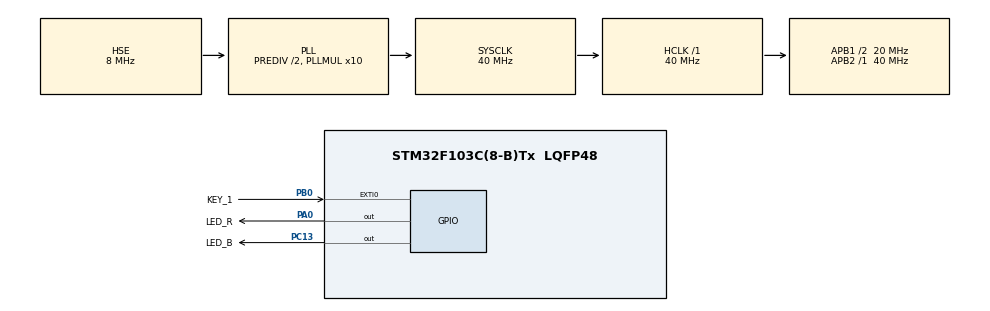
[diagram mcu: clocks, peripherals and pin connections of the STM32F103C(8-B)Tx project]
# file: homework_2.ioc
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Mcu.Family=STM32F1
Mcu.Name=STM32F103C(8-B)Tx
Mcu.Package=LQFP48
NVIC.EXTI0_IRQn=true\:3\:0\:true\:false\:true\:true\:true\:true
NVIC.PriorityGroup=NVIC_PRIORITYGROUP_4
NVIC.TIM3_IRQn=true\:0\:0\:false\:false\:true\:true\:true\:true
PA0-WKUP.GPIO_Label=LED_R
PA0-WKUP.PinState=GPIO_PIN_SET
PA0-WKUP.Signal=GPIO_Output
PA13.Mode=Serial_Wire
PA13.Signal=SYS_JTMS-SWDIO
PA14.Mode=Serial_Wire
PA14.Signal=SYS_JTCK-SWCLK
PB0.GPIO_Label=KEY_1
PB0.GPIO_ModeDefaultEXTI=GPIO_MODE_IT_RISING_FALLING
PB0.GPIO_PuPd=GPIO_PULLUP
PB0.Signal=GPXTI0
PC13-TAMPER-RTC.GPIO_Label=LED_B
PC13-TAMPER-RTC.Signal=GPIO_Output
PC14-OSC32_IN.Mode=LSE-External-Oscillator
PC14-OSC32_IN.Signal=RCC_OSC32_IN
PC15-OSC32_OUT.Mode=LSE-External-Oscillator
PC15-OSC32_OUT.Signal=RCC_OSC32_OUT
PD0-OSC_IN.Mode=HSE-External-Oscillator
PD0-OSC_IN.Signal=RCC_OSC_IN
PD1-OSC_OUT.Mode=HSE-External-Oscillator
PD1-OSC_OUT.Signal=RCC_OSC_OUT
ProjectManager.HeapSize=0x200
ProjectManager.StackSize=0x400
ProjectManager.TargetToolchain=MDK-ARM V5.32
RCC.AHBFreq_Value=40000000
RCC.APB1CLKDivider=RCC_HCLK_DIV2
RCC.APB1Freq_Value=20000000
RCC.APB1TimFreq_Value=40000000
RCC.APB2Freq_Value=40000000
RCC.APB2TimFreq_Value=40000000
RCC.HCLKFreq_Value=40000000
RCC.HSEDivPLL=RCC_HSE_PREDIV_DIV2
RCC.PLLMUL=RCC_PLL_MUL10
RCC.PLLSourceVirtual=RCC_PLLSOURCE_HSE
RCC.SYSCLKFreq_VALUE=40000000
RCC.SYSCLKSource=RCC_SYSCLKSOURCE_PLLCLK
RCC.USBFreq_Value=40000000
TIM3.AutoReloadPreload=TIM_AUTORELOAD_PRELOAD_ENABLE
TIM3.Period=3999
TIM3.Prescaler=1999
VP_TIM3_VS_ClockSourceINT.Mode=Internal
board=custom

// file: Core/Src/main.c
/* USER CODE BEGIN Header */
/**
  ******************************************************************************
  * @file           : main.c
  * @brief          : Main program body
  ******************************************************************************
  * @attention
  *
  * Copyright (c) 2026 STMicroelectronics.
  * All rights reserved.
  *
  * This software is licensed under terms that can be found in the LICENSE file
  * in the root directory of this software component.
  * If no LICENSE file comes with this software, it is provided AS-IS.
  *
  ******************************************************************************
  */
/* USER CODE END Header */
#include "main.h"
#include "tim.h"
#include "gpio.h"

/* USER CODE BEGIN PV */

//控制红色led灯开关与闪烁的变量
uint8_t key_state = 0;//记录按键的状态，未按下为0，按下为1
uint32_t last_time = 0;//上一次中断时间
uint32_t press_time = 0;//记录按下时间
uint32_t lift_time = 0;//记录抬起时间
uint8_t led_state = 0;//记录LED的状态，不闪烁为0，闪烁为1

/* USER CODE END PV */

void SystemClock_Config(void);

int main(void)
{

  /* MCU Configuration--------------------------------------------------------*/

  /* Reset of all peripherals, Initializes the Flash interface and the Systick. */
  HAL_Init();

  /* Configure the system clock */
  SystemClock_Config();

  /* Initialize all configured peripherals */
  MX_GPIO_Init();
  MX_TIM3_Init();

  /* Infinite loop */
  while (1)
  {

  }
}

void SystemClock_Config(void)
{
  RCC_OscInitTypeDef RCC_OscInitStruct = {0};
  RCC_ClkInitTypeDef RCC_ClkInitStruct = {0};

  /** Initializes the RCC Oscillators according to the specified parameters
  * in the RCC_OscInitTypeDef structure.
  */
  RCC_OscInitStruct.OscillatorType = RCC_OSCILLATORTYPE_HSE;
  RCC_OscInitStruct.HSEState = RCC_HSE_ON;
  RCC_OscInitStruct.HSEPredivValue = RCC_HSE_PREDIV_DIV2;
  RCC_OscInitStruct.HSIState = RCC_HSI_ON;
  RCC_OscInitStruct.PLL.PLLState = RCC_PLL_ON;
  RCC_OscInitStruct.PLL.PLLSource = RCC_PLLSOURCE_HSE;
  RCC_OscInitStruct.PLL.PLLMUL = RCC_PLL_MUL10;
  if (HAL_RCC_OscConfig(&RCC_OscInitStruct) != HAL_OK)
  {
    Error_Handler();
  }

  /** Initializes the CPU, AHB and APB buses clocks
  */
  RCC_ClkInitStruct.ClockType = RCC_CLOCKTYPE_HCLK|RCC_CLOCKTYPE_SYSCLK
                              |RCC_CLOCKTYPE_PCLK1|RCC_CLOCKTYPE_PCLK2;
  RCC_ClkInitStruct.SYSCLKSource = RCC_SYSCLKSOURCE_PLLCLK;
  RCC_ClkInitStruct.AHBCLKDivider = RCC_SYSCLK_DIV1;
  RCC_ClkInitStruct.APB1CLKDivider = RCC_HCLK_DIV2;
  RCC_ClkInitStruct.APB2CLKDivider = RCC_HCLK_DIV1;

  if (HAL_RCC_ClockConfig(&RCC_ClkInitStruct, FLASH_LATENCY_1) != HAL_OK)
  {
    Error_Handler();
  }
}

/* USER CODE BEGIN 4 */
//外部中断回调函数开始，判断按键状态与按下时间，同时消抖
void HAL_GPIO_EXTI_Callback(uint16_t GPIO_Pin)
{
	if (GPIO_Pin == KEY_1_Pin) {
		uint32_t current_time = HAL_GetTick();//获取中断时间

		if(current_time -last_time >20) {
			if (key_state == 0) { //按键未按下
				key_state = 1; //按键按下
				press_time = current_time; //记录按下时间
			}
			else if (key_state == 1) { //按键已按下
				lift_time = current_time; //记录抬起时间
				if (lift_time - press_time >= 1000) { //长按时间为1000ms
					if (led_state == 0) {//led不闪烁则开启闪烁
						HAL_TIM_Base_Start_IT(&htim3); //开启定时器中断，LED闪烁
						led_state = 1;
					}
					else if (led_state == 1) {//led闪烁则关闭闪烁
						HAL_TIM_Base_Stop_IT(&htim3); //关闭定时器中断，LED不闪烁
						led_state = 0;
					}
				}
				else if (lift_time - press_time < 1000){//判断短按
					HAL_GPIO_TogglePin(GPIOA, LED_R_Pin); //短按，LED翻转
				}
				key_state = 0; //按键状态复位
			}
		}
		last_time = current_time;//记录本次中断时间
	}
}

//定时器中断回调函数，控制LED闪烁
void HAL_TIM_PeriodElapsedCallback(TIM_HandleTypeDef* htim)
{
    if (htim->Instance == TIM3) {
        HAL_GPIO_TogglePin(GPIOA, LED_R_Pin );
    }
}
/* USER CODE END 4 */

void Error_Handler(void)
{
  __disable_irq();
  while (1)
  {
  }
}
